# psoc4200bl register map
Vendor: Cypress Semiconductor; Series: PSoC4200BL; File version: 1.0
CPU: CM0 r0p1, little endian, no MPU, no FPU, 2 interrupt priority bits
Registers are 32-bit, read-write, reset 0x0 unless marked. A register's access mark holds for its fields unless they carry their own. Offsets are from the block's base; [hi:lo] are bit positions; lines under a group give offsets from that group.

## BLE (part 1 of 5) — Bluetooth Low Energy Subsystem
Base 0x402E0000
0x00 BLERD group — #REF!
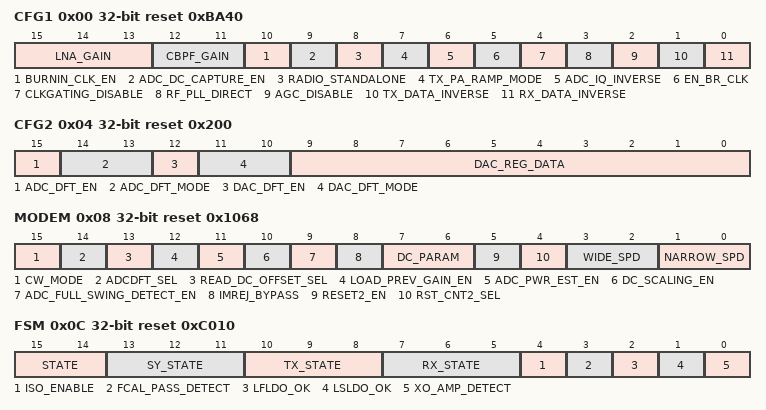
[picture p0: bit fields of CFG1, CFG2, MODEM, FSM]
  0x00 CFG1 reset 0xBA40 — Generic configure register.
    [15:13] LNA_GAIN — LNA+TIA manual gain setting when AGC is disabled by asserting bit[2]. The gain obtained is a function of the LNA gm as well as the TIA feedback resister. 000: VLG 001: LG 010: MH 011: IHG 100: HG 101: VHG 110, 111: Illegal Value
    [12:11] CBPF_GAIN — CBPF manually gain setting when AGC is disabled by asserting bit[2]. This gain is truly reflective of the voltage gain across the CBPF and is determined by the ratio of resisters 11: 15dB, 10: 12dB, 01: 3dB, 00: 0dB
    [10] BURNIN_CLK_EN — burn in function mode 1: digital main clock from clk_core. 0: digital main clock from HardIP
    [9] ADC_DC_CAPTURE_EN — 1: ADC DC capture enable
    [8] RADIO_STANDALONE — 1: radio standalone without link layer controller in SoC, Tx command from reg0x10[13] and RX command from reg0x10[12]
    [7] TX_PA_RAMP_MODE — 1:ramp to PA gain which given txpa_gain in 2dB steps, starting from min gain. 0: ramp to PA gin which given in txpa_gain in one short from min gain
    [6] ADC_IQ_INVERSE — 1: swap ADC I, Q path
    [5] EN_BR_CLK — 1: enable brclk output
    [4] CLKGATING_DISABLE — 1. disable the clock gating logic golbally. Indepenedent of any other cnditions. None of the clocks can be gated when this bit is set. 0: clock gating logic is enabled, the logic in clk_gen will determine which clocks are to be gated.
    [3] RF_PLL_DIRECT — program channel freqency as direct frequency mode. high active. When RF_PLL_DIRECT = 1, RF = reg0x10[11:0] Mhz. When RF_PLL_DIRECT = 0, RF = 2402 + 2*reg7[5:0] Mhz.
    [2] AGC_DISABLE — 1: disabel the AGC, the LNA+TIA and CBPF gain are given based on bits [15:11] of reg0.
    [1] TX_DATA_INVERSE — invert modulation transmit data, high active
    [0] RX_DATA_INVERSE — Invert demodulation receiving data,high active
  0x04 CFG2 reset 0x200 — Generic configure register.
    [15] ADC_DFT_EN — 1: ADC DFT enable
    [14:13] ADC_DFT_MODE — ADC DFT mode selection (Available on Atlantis TC only) 00: 3 sample I path data to read_i_adc_1. 3 sample Q path data to read_q_adc_2. 10: discard LSB both I and Q path data. 2 bytes I and Q path data to read_iq_adc with 6MHz updat 11: discard LSB both I and Q path data. 2 bytes I and Q path data to read_iq_adc with 3MHz updat
    [12] DAC_DFT_EN — 1: DAC DFT mode enable
    [11:10] DAC_DFT_MODE — DAC DFT mode definition 00: DAC input from dac_reg_data[9:0] 01: DAC input as 12Mhz increased value 10: DAC input as 1MHz Sine Wave 11: DAC input as 4MHz SIN wave
    [9:0] DAC_REG_DATA — DAC input from this register when CFG2_DAC_DFT_EN =1 and dft_mode = 2'b00
  0x08 MODEM reset 0x1068 — modem configuration
    [15] CW_MODE — 1: modulation continue wave output
    [14] ADCDFT_SEL — 1: ADC DFT capture data after image filter 0: ADC DFT capture data before image filter
    [13] READ_DC_OFFSET_SEL — 1: read back of analog DC CAL result. 0: read back of DC capture in digital
    [12] LOAD_PREV_GAIN_EN — 1: load previous RX packet gain setting at first gain change step 0: not load previous RX packet gain.
    [11] ADC_PWR_EST_EN — 1: power estimation for ADC output is enabled.
    [10] DC_SCALING_EN — 1: DC scaling is enabled in the Demodulator. The Scaling happens when CBPF gain changes.
    [9] ADC_FULL_SWING_DETECT_EN — 1: select new AGC methodology with ADC full swing detection
    [8] IMREJ_BYPASS — bypass image filter in demoulation
    [7:6] DC_PARAM — demodulation frequency deviation selection 00: 320K, 01: 350K, 10: 400K, 11:430K
    [5] RESET2_EN — demodulation soft reset enable, 0: diable, 1: enable soft reset
    [4] RST_CNT2_SEL — soft reset condition selection, 0: 32bits all ''0'/'1', 1: 16bits all '0'/'1'
    [3:2] WIDE_SPD — demodulation alpha value for DC offset tracking in wide speed 00: dc value times 8 01: dc value times 10 10: dc value times 12 11: dc value times 14
    [1:0] NARROW_SPD — set alpha value for dC offset tracking speed in narrow mode 00: dc value times 1 01: dc value times 2 10: dc value times 3 11: dc value times 4
  0x0C FSM ro reset 0xC010 — RFCTRL state information
    [15:14] STATE — RFCTRL major state, 00: sleep mode, 11: idle mode, 10: TX mode, 01: RX mode
    [13:11] SY_STATE — RFCTRL SYNTH state 000: SY off, 001: SY Regulator power up, 010: SY VCO pup up 011: SY LO path power up, 100: Frequency calibration, 101: PLL setting. 110: PLL locked 111: non existing SY FSM
    [10:8] TX_STATE — RFCTRL TX state 000: TX Off 001: TX Regulator Powerup 010: TX Baseband Powerup 011: KV Calibration 100: TX PLL Settling 101: TX Ready 110, 111: non existing TX FSM
    [7:5] RX_STATE — RFCTRL RX state 000: RX Off 001: RX Regulator Powerup 010: RX Baseband and IF Powerup 011: DC Calibration 100: RX Wait for PLL settling 101: RX ADC DC value capture 110: RX Receive ON 111: non existing RX FSM
    [4] ISO_ENABLE — monitor isolation cell enable signal 1: isolation cell enabled.
    [3] FCAL_PASS_DETECT — TX balun power detector, 1: Frequency calibration has passed. 0: Frequency calibration has failed
    [2] LFLDO_OK — 1: LF LDO powered up
    [1] LSLDO_OK — 1: LS LDO powered up
    [0] XO_AMP_DETECT — 1: XO is oscillating reached 60 percent ampitude. 0: XO is no oscillating or not reached 60 percent ampitude. BLERD_BB_XO[1] determines fast or normal charge. From MXIE(BLERF designer) confimation, XO within 50ppm needs 2 times of XO detection BLERD_BB_XO[1] XO_amp_detect XO stable 1 320us 640us 0 1120us 2.24ms
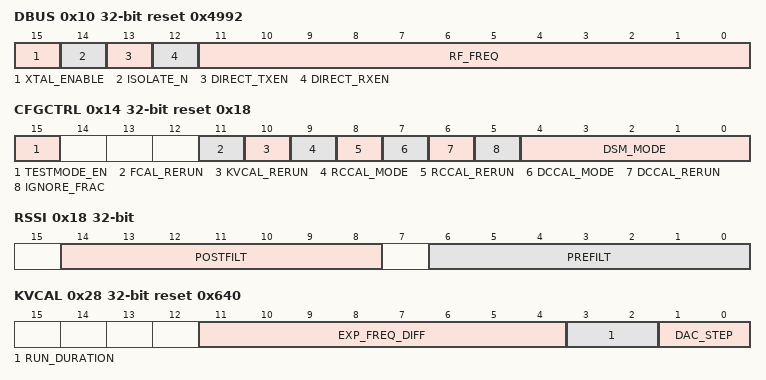
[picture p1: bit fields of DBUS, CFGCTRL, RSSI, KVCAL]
  0x10 DBUS reset 0x4992 — RFCTRL mode transition control
    [15] XTAL_ENABLE — crystal enable. High active
    [14] ISOLATE_N — force isolation cell enable of analog / digital boundary. low active
    [13] DIRECT_TXEN — When cfg1_radio_standalone =1, debus_direct_rxen replace dbus_rx_en
    [12] DIRECT_RXEN — When cfg1_radio_standalone =1, debus_direct_rxen replace dbus_rx_en
    [11:0] RF_FREQ — When CFG1_RF_PLL_DIRECT=1, RF frequency is direct program from DBUS register [11:0]
  0x14 CFGCTRL reset 0x18 — RFCTRL running configuration
    [15] TESTMODE_EN — 1: enables the test mode feature of RFCTRL
    [11] FCAL_RERUN — 1: KVCAL will be force rerun when cfgctrl_testmode_en = 1
    [10] KVCAL_RERUN — 1: FCAL will be force rerun when cfgctrl_testmode_en = 1
    [9] RCCAL_MODE — 0: normal mode 1: slow mode, The timer for each setp in calibration is doubled with normal mode
    [8] RCCAL_RERUN — 1: RC-cal force to rerun when cfgctrl_testmode_en = 1
    [7] DCCAL_MODE — 0: RX DC offset calibration in run normal mode 1: RX DC offset calibration is run in slow mode. Here each step in calibration is given double time compared to the normal mode
    [6] DCCAL_RERUN — 1: DC CAL is forced to run when cfgctrl_testmode_en = 1
    [5] IGNORE_FRAC — 0: Do not ignore fractional part in DSM (Frac-N PLL). 1: Ignore the fractional part in DSM (Int-N PLL).
    [4:0] DSM_MODE — Cfgctrl_dsm_mode[4]: 1'b0: Third order PLL is used in TX mode, this is not effective in RX mode 1'b1: First order PLL is used in TX mode, this is not effective in RX mode Cfgctrl_dsm_mode[3:2] The following bits determine the DSM mode in TX 00: Input dither but no initial condition for DSM 01: Input dither and initial condition to DSM. 10: No input dither and initial condition 11: No input dither but initial condition is given Cfgctrl_dsm_mode[1:0] The following bits determine the DSM mode in RX 00: Input dither but no initial condition for DSM 01: Input dither and initial condition to DSM. 10: No input dither and initial condition 11: No input dither but initial condition is given
  0x18 RSSI ro — RX envelpe detector and RSSI value
    [14:8] POSTFILT — RSSI value after the filter in digital, 0 represents -85dBm
    [6:0] PREFILT — RSSI value before the filter in thd digital, 0 represents -85dBm
  0x24 RMAP — BG LDO bypass mode
    [15:0] BB_BYPASS
  0x28 KVCAL reset 0x640 — KVCAL running configuration
    [11:4] EXP_FREQ_DIFF — This expected difference in KVCAL configuration counts(100 counts for an ideal modulalation path gain)
    [3:2] RUN_DURATION — This values tells by what value duration when FCAL is running. 00 : 25us. 01: 33.375us 10: 50us 11 : 100us
    [1:0] DAC_STEP — This values tells by what value should the DAC be offset from the mid-code, when the KVCAL is running. 00 : 512 (1MHz deviation). 01: 376 (0.75 Mhz deviation). 10: 256 (0.5 Mhz deviation) 11 : 128 (0.25 Mhz deviation
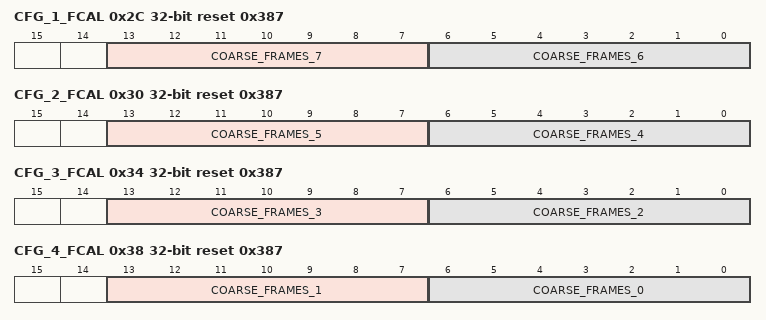
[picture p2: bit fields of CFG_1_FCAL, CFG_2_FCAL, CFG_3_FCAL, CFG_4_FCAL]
  0x2C CFG_1_FCAL reset 0x387 — FCAL running configure 5_6
    [13:7] COARSE_FRAMES_7 — numbere of frames to run for the calibration 7th coarse bit
    [6:0] COARSE_FRAMES_6 — numbere of frames to run for the calibration 6th coarse bit
  0x30 CFG_2_FCAL reset 0x387 — FCAL running configure 7_2
    [13:7] COARSE_FRAMES_5 — numbere of frames to run for the calibration 5th coarse bit
    [6:0] COARSE_FRAMES_4 — numbere of frames to run for the calibration 4th coarse bit
  0x34 CFG_3_FCAL reset 0x387 — FCAL running configure 3_4
    [13:7] COARSE_FRAMES_3 — numbere of frames to run for the calibration 3rd coarse bit
    [6:0] COARSE_FRAMES_2 — numbere of frames to run for the calibration 2nd coarse bit
  0x38 CFG_4_FCAL reset 0x387 — FCAL running configure 0_1
    [13:7] COARSE_FRAMES_1 — numbere of frames to run for the calibration 1st coarse bit
    [6:0] COARSE_FRAMES_0 — numbere of frames to run for the calibration 0th coarse bit
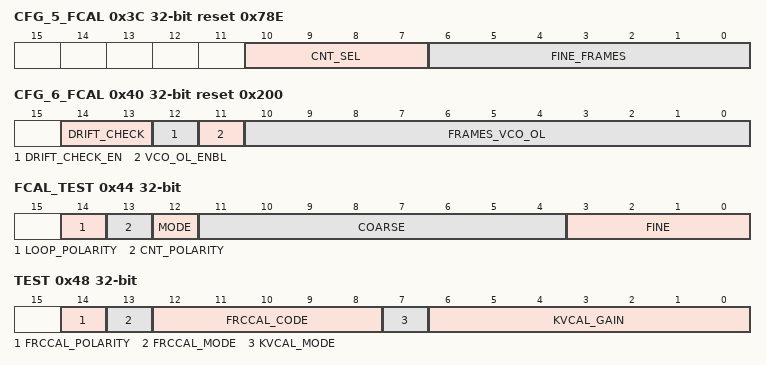
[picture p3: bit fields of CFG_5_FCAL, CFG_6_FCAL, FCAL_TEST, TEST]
  0x3C CFG_5_FCAL reset 0x78E — FCAL running framer fine
    [10:7] CNT_SEL — select which count should be reflected in the FCAL_DBG_2 and FCAL_DBG_3 registers 4'd1: FCAL 7th Coarse bit calibration 4'd2: FCAL 6th Coarse bit calibration 4'd3: FCAL 5th Coarse bit calibration 4'd4: FCAL 4th Coarse bit calibration 4'd5: FCAL 3rd Coarse bit calibration 4'd6: FCAL 2nd Coarse bit calibration 4'd7: FCAL 1st Coarse bit calibration 4'd8: FCAL 0th Coarse bit calibration 4'd9: FCAL 3rd Fine bit calibration 4'd10: FCAL 2nd Fine bit calibration 4'd11: FCAL 1st Fine bit calibration 4'd12: FCAL 0th Fine bit calibration 4'd13: VCO Open loop count 4'd14: KVCAL Observed Count 4'd15: KVCAL Gain Default: Gives zero output
    [6:0] FINE_FRAMES — numbere of frames to run for all the calibration of all the Fine bits
  0x40 CFG_6_FCAL reset 0x200 — FCAL running VCO OL
    [14:13] DRIFT_CHECK — 00: start drift check when the TX driver is powered up 01: start drift check measurement 100us after TX driver is power ed up 10: start drift check measurement 200us after the TX driver is powered up 11: start drift check measurement 300us after the TX drive is powered up
    [12] DRIFT_CHECK_EN — enables the FCAL drift check, This needs to be set prior to the TX burst being programmed as it affects the timing sequence. Ensure that FB buffer has not been powered down such that the FCAL counter is left alive. This requires a cahgne to reg0xcc[5] to be set to 0 (disable FB buffer power save). This needs to be set piror to placing the part in TX mode
    [11] VCO_OL_ENBL — 1:enable vco openloop characterization
    [10:0] FRAMES_VCO_OL — Number of frames to run in VCO openloop Characterization . If bit[12] 'fcal_drift_check_en' is asserted, then this field indicates for how many frames the FCAL drift has to be measured
  0x44 FCAL_TEST — FCAL test mode configuration
    [14] LOOP_POLARITY — 1: Inverts the polarity of the FCAL loop. In this mode the DCAP code is decreased if observed count is greater than target count. 0: This is normal FCAL loop, where DCAP code is increased if the observed count is greater than target_count
    [13] CNT_POLARITY — 1: Inverts the polarity of the FCAL counter output coming in to the RFCTRL
    [12] MODE — force the coarse and fine bits of FCAL output enable, high active
    [11:4] COARSE — force coarse bits output of the FCAL engine when test_mode is set
    [3:0] FINE — force fine bits output of the FCAL engine when test_mode is set
  0x48 TEST — RCCAL and procmon test configuration
    [14] FRCCAL_POLARITY — 1: invert RC CAL polarity.
    [13] FRCCAL_MODE — 1: RC-CAL code is forced to the given code
    [12:8] FRCCAL_CODE — this code is forced as the RC_CAL code when test_frccal_mode = 1
    [7] KVCAL_MODE — 1: KV-CAL code is forced to the given code
    [6:0] KVCAL_GAIN — this code is forced as the KV_CAL code when when test_kvcal_mode = 1
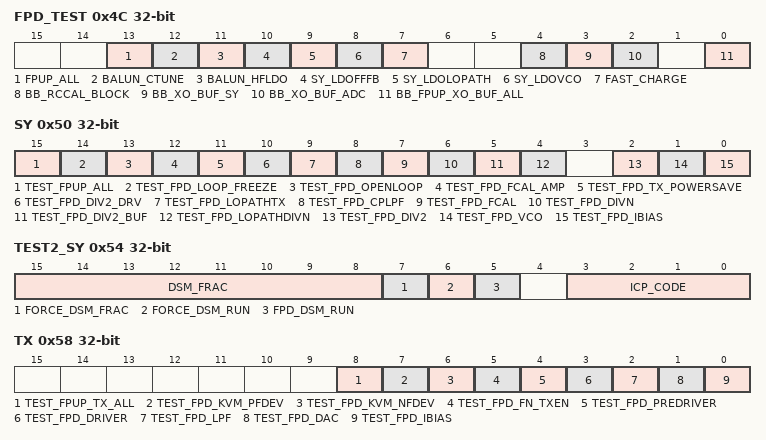
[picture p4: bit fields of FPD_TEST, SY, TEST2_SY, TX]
  0x4C FPD_TEST — LDOs test
    [13] FPUP_ALL — 1: This is used to force powerup the blocks controlled by this register. Fpd has higher precedence over force_powerup if cfgctrl_testmode_en = 1
    [12] BALUN_CTUNE — 1: force powerdown Balun Ctune block if cfgctrl_testmode_en = 1
    [11] BALUN_HFLDO — 1: Balun HF LDO is forced power down if cfgctrl_testmode_en = 1
    [10] SY_LDOFFFB — 1: force power down SY LDO LOFFFB if cfgctrl_testmode_en = 1
    [9] SY_LDOLOPATH — 1: force power down SY LDO LOPATH if cfgctrl_testmode_en = 1
    [8] SY_LDOVCO — 1: force power down SY LDOVCO if cfgctrl_testmode_en = 1
    [7] FAST_CHARGE — 1: force power the fast charge bit for LDO Lopath if cfgctrl_testmode_en = 1
    [4] BB_RCCAL_BLOCK — 1: forcefully powers down the RC CAL block if cfgctrl_testmode_en = 1
    [3] BB_XO_BUF_SY — 1: forcefully powers down xo buffer to synth if cfgctrl_testmode_en = 1
    [2] BB_XO_BUF_ADC — 1: forcefully powers down xo buffer to ADC if cfgctrl_testmode_en = 1
    [0] BB_FPUP_XO_BUF_ALL — 1: forcefully powers down all the buffers in XO if cfgctrl_testmode_en = 1
  0x50 SY — SY test configuration 1
    [15] TEST_FPUP_ALL — 1: all the blocks in SY are forced power up if cfgctrl_testmode_en = 1
    [14] TEST_FPD_LOOP_FREEZE — 1: loop freeze is forced low if cfgctrl_testmode_en = 1
    [13] TEST_FPD_OPENLOOP — The loop_freeze is forced low if this bit is asserted and cfgctrl_testmode_en = 1
    [12] TEST_FPD_FCAL_AMP — The fcal amp is forced powered down, if this bit is asserted and cfgctrl_testmode_en = 1
    [11] TEST_FPD_TX_POWERSAVE — The fcal amp is forced powered down, if this bit is asserted and cfgctrl_testmode_en = 1
    [10] TEST_FPD_DIV2_DRV — the TX powersave bit si force to zero if this bit is asserted and and cfgctrl_testmode_en = 1
    [9] TEST_FPD_LOPATHTX — SY LOpath TX buffer is forced powered down, if this bit is set and cfgctrl_testmode_en = 1
    [8] TEST_FPD_CPLPF — SY CP and LPF are forced powered down, if this bit is set and cfgctrl_testmode_en = 1
    [7] TEST_FPD_FCAL — SY FCAL counter is forced powered down, if this bit is set and cfgctrl_testmode_en = 1
    [6] TEST_FPD_DIVN — SY DIVN block is forced powered down, if this bit is set and cfgctrl_testmode_en = 1
    [5] TEST_FPD_DIV2_BUF — SY LOpath FCAL buffer is forced powered down, if this bit is set and cfgctrl_testmode_en = 1
    [4] TEST_FPD_LOPATHDIVN — SY LOpath DIVN buffer is forced powered down, if this bit is set and cfgctrl_testmode_en = 1
    [2] TEST_FPD_DIV2 — SY high speed divider block is forced powered down, if this bit is set and cfgctrl_testmode_en = 1
    [1] TEST_FPD_VCO — SY VCO block is forced powered down, if this bit is set and RF_TST_EN = 1
    [0] TEST_FPD_IBIAS — SY IBIAS block is forced powered down, if this bit is set and cfgctrl_testmode_en = 1
  0x54 TEST2_SY — SY test configuration 2
    [15:8] DSM_FRAC — fore bits for DSM fractional bits if test2_sy_force_dsm_frac=1
    [7] FORCE_DSM_FRAC — 1: Force the MSB 8bit of the DSM fractional part with Reg[15-8]. The LSB bits should be 0. 0: DSM fractional bits will be driven by Timing Engine
    [6] FORCE_DSM_RUN — DSM_run signal is asserted if this bit is set and rfctrl_testmode_en = 1
    [5] FPD_DSM_RUN — DSM run signal is de-asserted if this bit si set and rfctrl_testmode_en = 1
    [3:0] ICP_CODE — ICP code will be programmed with these bits.
  0x58 TX — transmit test configuration
    [8] TEST_FPUP_TX_ALL — force powerup all the TX blocks if rfctrl_testmode_en = 1
    [7] TEST_FPD_KVM_PFDEV — modulator will not enable positive 1Mhz frequency deviation mode, if this bit is set and rfctrl_testmdoe_en = 1
    [6] TEST_FPD_KVM_NFDEV — modulator will not enable negative 1Mhz frequency deviation mode, if this bit is set and rfctrl_testmdoe_en = 1
    [5] TEST_FPD_FN_TXEN — the modulator control signal f_n_txen is deasswerted, if this bit is set and rfctrl_testmode_en = 1
    [4] TEST_FPD_PREDRIVER — 1: forced power down TX pre-drive if rfctrl_testmode_en = 1
    [3] TEST_FPD_DRIVER — 1: forced power down TX driver if rfctrl_testmode_en = 1
    [2] TEST_FPD_LPF — 1: forced power down TX LPF if rfctrl_testmode_en = 1
    [1] TEST_FPD_DAC — 1: forced power down TX DAC if rfctrl_testmode_en = 1
    [0] TEST_FPD_IBIAS — 1: forced power down TX ibias if rfctrl_testmode_en = 1
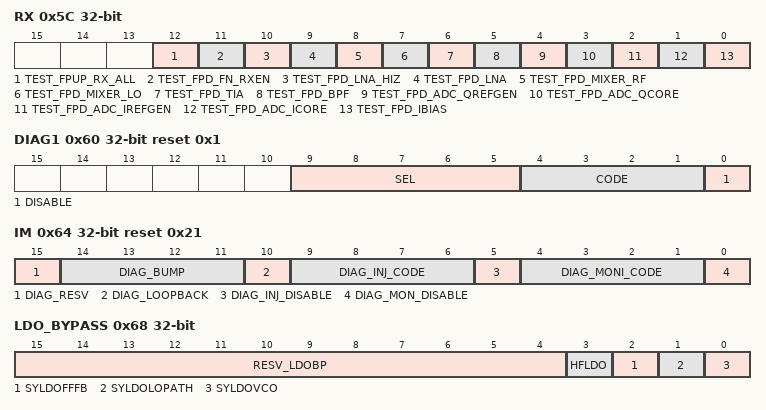
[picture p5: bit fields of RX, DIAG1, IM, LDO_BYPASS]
  0x5C RX — RX test configuration
    [12] TEST_FPUP_RX_ALL — 1:force powerup all RX blocks,if this bit is set and rfctrl_testmode_en = 1
    [11] TEST_FPD_FN_RXEN — 1:the demodulator control signal f_n_rxen is deasserted if this bit is set and rfctrl_tesmode_en=1
    [10] TEST_FPD_LNA_HIZ — 1:LNA HIZ signal is deasserted, if this bit is set and rfctrl_testmode_en = 1
    [9] TEST_FPD_LNA — 1: force power down RX LNA if this bit is set and rfctrl_testmode_en = 1
    [8] TEST_FPD_MIXER_RF — 1: force power down RX MIXER RF block if rfctrl_testmode_en = 1.
    [7] TEST_FPD_MIXER_LO — 1:force power down RX MIXER LO block if this bit is set and rfctrl_testmode_en = 1
    [6] TEST_FPD_TIA — 1:force power down RX TIA if this bit is set and rfctrl_testmode_en = 1
    [5] TEST_FPD_BPF — 1:force power down RX BPF, if this bit is set and rfctrl_testmode_en = 1
    [4] TEST_FPD_ADC_QREFGEN — 1:force power donw RX ADC QREF generation lock,if this bit is set and rfctrl_testmode_en = 1
    [3] TEST_FPD_ADC_QCORE — 1:force power down RX ADC Q Core block is force powerdown if this bit is set and rfctrl_testmode_en = 1
    [2] TEST_FPD_ADC_IREFGEN — 1:force power donw RX ADC IREF generation lock,if this bit is set and rfctrl_testmode_en = 1
    [1] TEST_FPD_ADC_ICORE — 1:force power down RX ADC I Core block is force powerdown if this bit is set and rfctrl_testmode_en = 1
    [0] TEST_FPD_IBIAS — 1:force power down RX IBIAS block if this bit is set and rfctrl_testmode_en = 1
  0x60 DIAG1 reset 0x1 — RF diagnostics configuration 1
    [9:5] SEL
    [4:1] CODE — global diagnositic code, this is given to all the blocks. The block wihich has the diagnostics enabled will decode this code
    [0] DISABLE — 1: diagnaositcs for all blocks are disabled 0: diagnostics are enabled at global level. The diagnostics for each block is controlled by a corresponding block level diag_enable signal
  0x64 IM reset 0x21 — inject monitor configuration
    [15] DIAG_RESV
    [14:11] DIAG_BUMP — diag bump code im_diag_bump[3:2] 2'b00: Mon OTA ref. voltage is 0.9V 2'b01: Mon OTA ref: vlotage is 1.0V 2'b10: Mon OTA ref: vlotage is 1.1V 2'b11: Mon OTA ref: vlotage is 0.8V im_diag_bump[1:0] 2'b00: Inj OTA ref. voltage is 0.9V 2'b01: Inj OTA ref: vlotage is 1.0V 2'b10: Inj OTA ref: vlotage is 1.1V 2'b11: Inj OTA ref: vlotage is 0.8V
    [10] DIAG_LOOPBACK — 1: This will be used to monitor various outputs in the chip and inject them to on-chip ADC 0: no monitor to injection loopback
    [9:6] DIAG_INJ_CODE — injection code. This determines for which block the injection enabled Code: inj_p inj_n 4'h1: vin_lpf unused 4'd 4 I TIA in_p I TIA in_n 4'd 5 Q TIA in_p Q TIA in_n 4'd 6 I TIA in_p Q TIA in_n 4'd 7 Q TIA in_p I TIA in_n 4'd 8 I ADC in_p I ADC in_n 4'd 9 Q ADC in_p Q ADC in_n 4'h0, 4'd2, 4'd2, 4'd10, 4'd11, 4'd12, 4'd13, 4'd14, 4'd15 are unused
    [5] DIAG_INJ_DISABLE — 1:globally disable the injection
    [4:1] DIAG_MONI_CODE — monitor code, this determines from lock how the monitor is being driven: Code moni_p moni_n 4'd 1 dac_outp gnd 4'd 2 lpf_out gnd 4'd 4 I TIA out_p I TIA out_n 4'd 5 Q TIA out_p Q TIA out_n 4'd 6 I CBPF out_p I CBPF out_n 4'd 7 Q CBPF out_p Q CBPF out_n 4'd 8 I CBPF out_p Q CBPF out_n 4'd 9 Q CBPF out_p I CBPF out_n 4'd0, 4'd3, 4'd10, 4'd11, 4'd12, 4'd13, 4'd14, 4'd15: unused
    [0] DIAG_MON_DISABLE — 1:globally disable the monitor
  0x68 LDO_BYPASS — LDOs bypass configuration
    [15:4] RESV_LDOBP
    [3] HFLDO — 1: BB SY HF LDO is bypassed. It should not be enable if line voltage is more than 2.1V. This bit should not toggle in scan mode
    [2] SYLDOFFFB — 1: Synth LDO_FFFB is bypassed. It should not be enable if line voltage is more than 2.1V. This bit should not toggle in scan mode
    [1] SYLDOLOPATH — 1: Synth LDO_LOPATH is bypassed. It should not be enable if line voltage is more than 2.1V. This bit should not toggle in scan mode
    [0] SYLDOVCO — 1: Synth LDO_VCO is bypassed. It should not be enable if line voltage is more than 2.1V. This bit should not toggle in scan mode
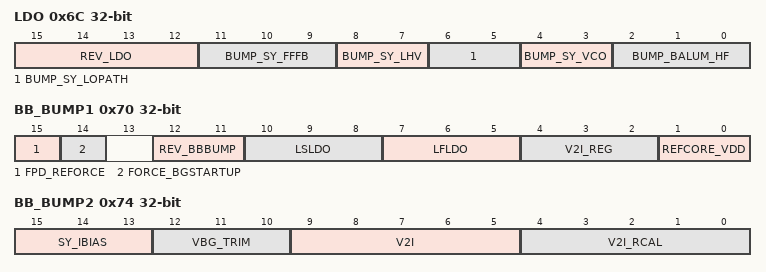
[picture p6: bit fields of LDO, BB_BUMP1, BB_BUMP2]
  0x6C LDO — bump bit for LDOs Atlantis
    [15:12] REV_LDO — received for feature
    [11:9] BUMP_SY_FFFB — 3'd0: FF and FB LDO outputs are 1.800V 3'd1: FF and FB LDO outputs are 1.846V 3'd2: FF and FB LDO outputs are 1.894V 3'd3: FF and FB LDO outputs are 1.946V 3'd4: FF and FB LDO outputs are 2.000V 3'd5: FF and FB LDO outputs are 1.649V 3'd6: FF and FB LDO outputs are 1.701V 3'd7: FF and FB LDO outputs are 1.756V
    [8:7] BUMP_SY_LHV — 2'd0: HV LDO outputs are 1.894V 2'd1: HV LDO outputs are 2.000V 2'd2: HV LDO outputs are 1.800V 2'd3: HV LDO outputs are 1.846V
    [6:5] BUMP_SY_LOPATH — 2'd0: LOPATH LDO outputs are 1.762V 2'd1: LOPATH LDO outputs are 1.861V 2'd2: LOPATH LDO outputs are 1.673V 2'd3: LOPATH LDO outputs are 1.716V
    [4:3] BUMP_SY_VCO — 2'd0: VCO LDO outputs are 1.413V 2'd1: VCO LDO outputs are 1.494V 2'd2: VCO LDO outputs are 1.329V 2'd3: VCO LDO outputs are 1.371V
    [2:0] BUMP_BALUM_HF — 3'd0: HF LDO output is 1.800V 3'd1: HF LDO output is 1.846V 3'd2: HF LDO output is 1.894V 3'd3: HF LDO output is 1.946V 3'd4: HF LDO output is 2.000V 3'd5: HF LDO output is 1.649V 3'd6: HF LDO output is 1.701V 3'd7: HF LDO output is 1.756V
  0x70 BB_BUMP1 — bump bit for LDOs BB,TXRX
    [15] FPD_REFORCE — 1: Force Power down for refcore
    [14] FORCE_BGSTARTUP — 1: force BG start u\p
    [12:11] REV_BBBUMP
    [10:8] LSLDO — 3'd0: LS LDO output is 1.708V 3'd1: LS LDO output is 1.747V 3'd2: LS LDO output is 1.802V 3'd3: LS LDO output is 1.849V 3'd4: LS LDO output is 1.904V 3'd5: LS LDO output is 1.552V 3'd6: LS LDO output is 1.591V 3'd7: LS LDO output is 1.650V
    [7:5] LFLDO — 3'd0: XO LDO output is 1.894V; BB LDO output is 1.800V 3'd1: XO LDO output is 1.946V; BB LDO output is 1.846V 3'd2: XO LDO output is 2.000V; BB LDO output is 1.894V 3'd3: XO LDO output is 2.000V; BB LDO output is 1.946V 3'd4: XO LDO output is 1.701V; BB LDO output is 1.649V 3'd5: XO LDO output is 1.756V; BB LDO output is 1.649V 3'd6: XO LDO output is 1.800V; BB LDO output is 1.701V 3'd7: XO LDO output is 1.846V; BB LDO output is 1.756V
    [4:2] V2I_REG — Bit[4] 1: Error amp quiescent current is 5u 0: Error amp quiescent current is 10u Bit[3:2] 2'd0: V2I LDO output is 1.8V 2'd1: V2I LDO output is 1.85V 2'd2: V2I LDO output is 1.9V 2'd3: V2I LDO output is 1.75V
    [1:0] REFCORE_VDD — 2'd0: Bumps the Ibias current of Refcore to 10u 2'd1: Bumps the Ibias current of Refcore to 9.1u 2'd2: Bumps the Ibias current of Refcore to 11.1u 2'd3: Bumps the Ibias current of Refcore to 12.5u
  0x74 BB_BUMP2 — BB bump configuration
    [15:13] SY_IBIAS — 3'b1xx: RCAL current bumped 3'b0xx: BG current bumped. 2'bxx: reperesent current bump 01: +12.5 percent, 00: 0 percent, 11: -12.5 percent, 10:-25 percent
    [12:10] VBG_TRIM — 3'd0: Trims the Bandgap voltage by 0 percent 3'd1: Trims the Bandgap voltage by 1.6 percent 3'd2: Trims the Bandgap voltage by 3.2 percent 3'd3: Trims the Bandgap voltage by 4.8 percent 3'd4: Trims the Bandgap voltage by 6.4 percent 3'd5: Trims the Bandgap voltage by -4.8 percent 3'd6: Trims the Bandgap voltage by -3.2 percent 3'd7: Trims the Bandgap voltage by -1.6 percent
    [9:5] V2I — Bit[9] 1: Error amp quiescent current is 5u 0: Error amp quiescent current is 10u Bit[8:5] 4'd0: Trims the BGR current by 0 percent 4'd1: Trims the BGR current by -2.5 percent 4'd2: Trims the BGR current by -5 percent 4'd3: Trims the BGR current by -7.5 percent 4'd4: Trims the BGR current by -10 percent 4'd5: Trims the BGR current by -12.5 percent 4'd6: Trims the BGR current by -15 percent 4'd7: Trims the BGR current by -17.5 percent 4'd8: Trims the BGR current by 20 percent 4'd9: Trims the BGR current by 17.5 percent 4'd10: Trims the BGR current by 15 percent 4'd11: Trims the BGR current by 12.5 percent 4'd12: Trims the BGR current by 10 percent 4'd13: Trims the BGR current by 7.5 percent 4'd14: Trims the BGR current by 5 percent 4'd15: Trims the BGR current by 2.5 percent
    [4:0] V2I_RCAL — Bit[4] 1: Error amp quiescent current is 5u 0: Error amp quiescent current is 10u Bit[3:0] 4'd0: Trims the RCAL current by 0 percent 4'd1: Trims the RCAL current by -2.5 percent 4'd2: Trims the RCAL current by -5 percent 4'd3: Trims the RCAL current by -7.5 percent 4'd4: Trims the RCAL current by -10 percent 4'd5: Trims the BGR current by -12.5 percent 4'd6: Trims the BGR current by -15 percent 4'd7: Trims the BGR current by -17.5 percent 4'd8: Trims the BGR current by 20 percent 4'd9: Trims the BGR current by 17.5 percent 4'd10: Trims the BGR current by 15 percent 4'd11: Trims the BGR current by 12.5 percent 4'd12: Trims the BGR current by 10 percent 4'd13: Trims the BGR current by 7.5 percent 4'd14: Trims the BGR current by 5 percent 4'd15: Trims the BGR current by 2.5 percent
